# M031AE_v1 register map
File version: 1.0
Registers are 32-bit, read-write, reset 0x0 unless marked. A register's access mark holds for its fields unless they carry their own. Offsets are from the block's base; [hi:lo] are bit positions; {n}, {i} and the like mark numbered series.

## SYS — SYS Register Map
Base 0x40000000
0x00 SYS_PDID ro reset not defined — Part Device Identification Number Register
  [31:0] PDID — Part Device Identification Number (Read Only). This register reflects device part number code. Software can read this register to identify which device is used.
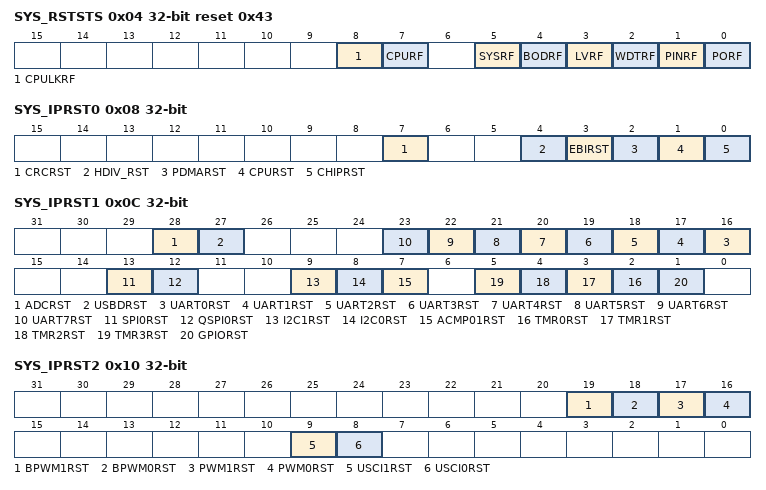
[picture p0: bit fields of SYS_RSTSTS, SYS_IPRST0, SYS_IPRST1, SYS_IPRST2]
0x04 SYS_RSTSTS reset 0x43 — System Reset Status Register
  [8] CPULKRF — CPU Lockup Reset Flag. Note: Write 1 to clear this bit to 0. Note 2: When CPU lockup happened under ICE is connected, This flag will set to 1 but chip will not reset.
    0=No reset from CPU lockup happened; 1=The Cortex-M0 lockup happened and chip is reset
  [7] CPURF — CPU Reset Flag. The CPU reset flag is set by hardware if software writes CPURST (SYS_IPRST0[1]) 1 to reset Cortex- M0 Core and Flash Memory Controller (FMC). Note: Write to clear this bit to 0.
    0=No reset from CPU; 1=The Cortex-M0 Core and FMC are reset by software setting CPURST to 1
  [5] SYSRF — System Reset Flag. The system reset flag is set by the 'Reset Signal' from the Cortex-M0 Core to indicate the previous reset source. Note: Write 1 to clear this bit to 0.
    0=No reset from Cortex-M0; 1=The Cortex- M0 had issued the reset signal to reset the system by writing 1 to the bit SYSRESETREQ(AIRCR[2], Application Interrupt and Reset Control Register, address = 0xE000ED0C) in system control registers of Cortex-M0 core
  [4] BODRF — BOD Reset Flag. The BOD reset flag is set by the 'Reset Signal' from the Brown-Out Detector to indicate the previous reset source. Note: Write 1 to clear this bit to 0.
    0=No reset from BOD; 1=The BOD had issued the reset signal to reset the system
  [3] LVRF — LVR Reset Flag. The LVR reset flag is set by the 'Reset Signal' from the Low Voltage Reset Controller to indicate the previous reset source. Note: Write 1 to clear this bit to 0.
    0=No reset from LVR; 1=LVR controller had issued the reset signal to reset the system
  [2] WDTRF — WDT Reset Flag. The WDT reset flag is set by the 'Reset Signal' from the Watchdog Timer or Window Watchdog Timer to indicate the previous reset source. Note 1: Write 1 to clear this bit to 0. Note 2: Watchdog Timer register RSTF(WDT_CTL[2]) bit is set if the system has been reset by WDT time-out reset. Window Watchdog Timer register WWDTRF(WWDT_STATUS[1]) bit is set if the system has been reset by WWDT time-out reset.
    0=No reset from watchdog timer or window watchdog timer; 1=The watchdog timer or window watchdog timer had issued the reset signal to reset the system
  [1] PINRF — NRESET Pin Reset Flag. The nRESET pin reset flag is set by the 'Reset Signal' from the nRESET Pin to indicate the previous reset source. Note: Write 1 to clear this bit to 0.
    0=No reset from nRESET pin; 1=Pin nRESET had issued the reset signal to reset the system
  [0] PORF — POR Reset Flag. The POR reset flag is set by the 'Reset Signal' from the Power-on Reset (POR) Controller or bit CHIPRST (SYS_IPRST0[0]) to indicate the previous reset source. Note: Write 1 to clear this bit to 0.
    0=No reset from POR or CHIPRST; 1=Power-on Reset (POR) or CHIPRST had issued the reset signal to reset the system
0x08 SYS_IPRST0 — Peripheral Reset Control Register 0
  [7] CRCRST — CRC Calculation Controller Reset (Write Protect). Set this bit to 1 will generate a reset signal to the CRC calculation controller. User needs to set this bit to 0 to release from the reset state. Note: This bit is write protected. Refer to the SYS_REGLCTL register.
    0=CRC calculation controller normal operation; 1=CRC calculation controller reset
  [4] HDIV_RST — HDIV Controller Reset (Write Protect). Set this bit to 1 will generate a reset signal to the hardware divider. User need to set this bit to 0 to release from the reset state. Note: This bit is write protected. Refer to the SYS_REGLCTL register.
    0=Hardware divider controller normal operation; 1=Hardware divider controller reset
  [3] EBIRST — EBI Controller Reset (Write Protect). Set this bit to 1 will generate a reset signal to the EBI. User needs to set this bit to 0 to release from the reset state. Note: This bit is write protected. Refer to the SYS_REGLCTL register.
    0=EBI controller normal operation; 1=EBI controller reset
  [2] PDMARST — PDMA Controller Reset (Write Protect). Setting this bit to 1 will generate a reset signal to the PDMA. User needs to set this bit to 0 to release from reset state. Note: This bit is write protected. Refer to the SYS_REGLCTL register.
    0=PDMA controller normal operation; 1=PDMA controller reset
  [1] CPURST — Processor Core One-shot Reset (Write Protect). Setting this bit will only reset the processor core and Flash Memory Controller(FMC), and this bit will automatically return to 0 after the 2 clock cycles. Note: This bit is write protected. Refer to the SYS_REGLCTL register.
    0=Processor core normal operation; 1=Processor core one-shot reset
  [0] CHIPRST — Chip One-shot Reset (Write Protect). Setting this bit will reset the whole chip, including Processor core and all peripherals, and this bit will automatically return to 0 after the 2 clock cycles. The CHIPRST is same as the POR reset, all the chip controllers is reset and the chip setting from Flash are also reload. About the difference between CHIPRST and SYSRESETREQ(AIRCR[2]), please refer to section 6.2.2. Note: This bit is write protected. Refer to the SYS_REGLCTL register. Note : reset by powr on reset
    0=Chip normal operation; 1=Chip one-shot reset
0x0C SYS_IPRST1 — Peripheral Reset Control Register 1
  [28] ADCRST — ADC Controller Reset
    0=ADC controller normal operation; 1=ADC controller reset
  [27] USBDRST — USBD Controller Reset
    0=USBD controller normal operation; 1=USBD controller reset
  [n+16] UART{n}RST (n=0..7) — UART{n} Controller Reset
    0=UART{n} controller normal operation; 1=UART{n} controller reset
  [13] SPI0RST — SPI0 Controller Reset
    0=SPI0 controller normal operation; 1=SPI0 controller reset
  [12] QSPI0RST — QSPI0 Controller Reset
    0=QSPI0 controller normal operation; 1=QSPI0 controller reset
  [9] I2C1RST — I2C1 Controller Reset
    0=I2C1 controller normal operation; 1=I2C1 controller reset
  [8] I2C0RST — I2C0 Controller Reset
    0=I2C0 controller normal operation; 1=I2C0 controller reset
  [7] ACMP01RST — Analog Comparator 0/1 Controller Reset
    0=Analog Comparator 0/1 controller normal operation; 1=Analog Comparator 0/1 controller reset
  [n+2] TMR{n}RST (n=0..3) — Timer{n} Controller Reset
    0=Timer{n} controller normal operation; 1=Timer{n} controller reset
  [1] GPIORST — GPIO Controller Reset
    0=GPIO controller normal operation; 1=GPIO controller reset
0x10 SYS_IPRST2 — Peripheral Reset Control Register 2
  [19] BPWM1RST — BPWM1 Controller Reset
    0=BPWM1 controller normal operation; 1=BPWM1 controller reset
  [18] BPWM0RST — BPWM0 Controller Reset
    0=BPWM0 controller normal operation; 1=BPWM0 controller reset
  [17] PWM1RST — PWM1 Controller Reset
    0=PWM1 controller normal operation; 1=PWM1 controller reset
  [16] PWM0RST — PWM0 Controller Reset
    0=PWM0 controller normal operation; 1=PWM0 controller reset
  [9] USCI1RST — USCI1 Controller Reset
    0=USCI1 controller normal operation; 1=USCI1 controller reset
  [8] USCI0RST — USCI0 Controller Reset
    0=USCI0 controller normal operation; 1=USCI0 controller reset
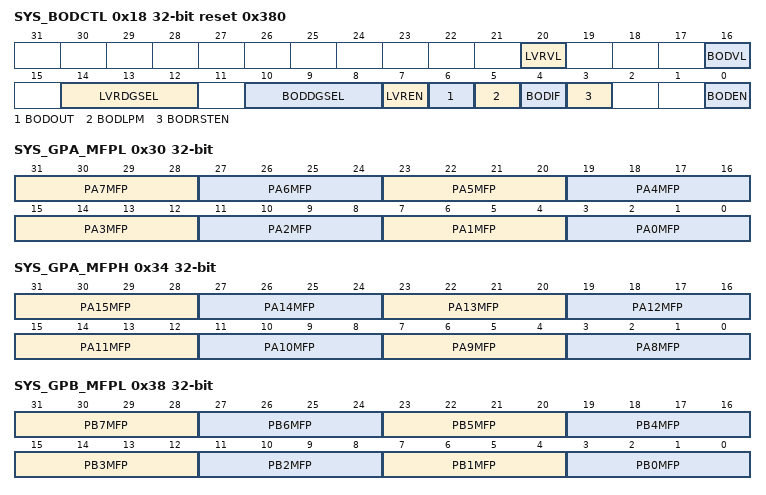
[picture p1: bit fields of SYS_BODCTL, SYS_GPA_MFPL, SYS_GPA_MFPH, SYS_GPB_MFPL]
0x18 SYS_BODCTL reset 0x380 (reset mask 0xFF00FFF0) — Brown-out Detector Control Register
  [20] LVRVL — LVR Detector Threshold Voltage Selection (Write Protect). The default value is set by Flash controller user configuration register LVRLVSEL (CONFIG0 [29]). Note 1: This bit is write protected. Refer to the SYS_REGLCTL register. Note 2: This bit is only for special case. Note 3: reset by powr on reset
    0=LVR-Out Detector threshold voltage is 1.6V; 1=LVR-Out Detector threshold voltage is 1.7V
  [16] BODVL — Brown-out Detector Threshold Voltage Selection (Write Protect). The default value is set by Flash controller user configuration register CBOV (CONFIG0 [21]). Note: This bit is write protected. Refer to the SYS_REGLCTL register. Note : reset by powr on reset
    0=Brown-Out Detector threshold voltage is 2.0V; 1=Brown-Out Detector threshold voltage is 2.5V
  [14:12] LVRDGSEL — LVR Output De-glitch Time Select (Write Protect). Note: These bits are write protected. Refer to the SYS_REGLCTL register.
    0=Without de-glitch function; 1=64 system clock (HCLK); 2=128 system clock (HCLK); 3=256 system clock (HCLK); 4=512 system clock (HCLK); 5=1024 system clock (HCLK); 6=2048 system clock (HCLK); 7=4096 system clock (HCLK)
  [10:8] BODDGSEL — Brown-out Detector Output De-glitch Time Select (Write Protect). Note: These bits are write protected. Refer to the SYS_REGLCTL register.
    0=BOD output is sampled by LIRC/4 clock; 1=64 system clock (HCLK); 2=128 system clock (HCLK); 3=256 system clock (HCLK); 4=512 system clock (HCLK); 5=1024 system clock (HCLK); 6=2048 system clock (HCLK); 7=4096 system clock (HCLK)
  [7] LVREN — Low Voltage Reset Enable Bit (Write Protect). The LVR function resets the chip when the input power voltage is lower than LVR circuit setting. LVR function is enabled by default. Note 1: After enabling the bit, the LVR function will be active with 200us delay for LVR output stable (default). Note 2: This bit is write protected. Refer to the SYS_REGLCTL register.
    0=Low Voltage Reset function Disabled; 1=Low Voltage Reset function Enabled
  [6] BODOUT — Brown-out Detector Output Status. It means the detected voltage is lower than BODVL setting. If the BODEN is 0, BOD function disabled , this bit always responds 0000.
    0=Brown-out Detector output status is 0; 1=Brown-out Detector output status is 1
  [5] BODLPM — Brown-out Detector Low Power Mode (Write Protect). Note 1: The BOD consumes about 100uA in normal mode, the low power mode can reduce the current to about 1/10 but slow the BOD response. Note 2: This bit is write protected. Refer to the SYS_REGLCTL register.
    0=BOD operate in normal mode (default); 1=BOD Low Power mode Enabled
  [4] BODIF — Brown-out Detector Interrupt Flag. Note: Write 1 to clear this bit to 0.
    0=Brown-out Detector does not detect any voltage draft at VDD down through or up through the voltage of BODVL setting; 1=When Brown-out Detector detects the VDD is dropped down through the voltage of BODVL setting or the VDD is raised up through the voltage of BODVL setting, this bit is set to 1 and the brown-out interrupt is requested if brown-out interrupt is enabled
  [3] BODRSTEN — Brown-out Reset Enable Bit (Write Protect). The default value is set by Flash controller user configuration register CBORST(CONFIG0[20]) bit . Note 1: While the Brown-out Detector function is enabled (BODEN high) and BOD reset function is enabled (BODRSTEN high), BOD will assert a signal to reset chip when the detected voltage is lower than the threshold (BODOUT high). While the BOD function is enabled (BODEN high) and BOD interrupt function is enabled (BODRSTEN low), BOD will assert an interrupt if BODOUT is high. BOD interrupt will keep till to the BODEN set to 0. BOD interrupt can be blocked by disabling the NVIC BOD interrupt or disabling BOD function (set BODEN low). Note 2: This bit is write protected. Refer to the SYS_REGLCTL register. Note 3: Reset by powr on reset
    0=Brown-out 'INTERRUPT' function Enabled; 1=Brown-out 'RESET' function Enabled
  [0] BODEN — Brown-out Detector Enable Bit (Write Protect). The default value is set by Flash controller user configuration register CBODEN (CONFIG0 [19]). Note 1: This bit is write protected. Refer to the SYS_REGLCTL register. Note 2: Reset by powr on reset
    0=Brown-out Detector function Disabled; 1=Brown-out Detector function Enabled
0x24 SYS_PORCTL — Power-On-reset Controller Register
  [15:0] POROFF — Power-on Reset Enable Bit (Write Protect). When powered on, the POR circuit generates a reset signal to reset the whole chip function, but noise on the power may cause the POR active again. User can disable internal POR circuit to avoid unpredictable noise to cause chip reset by writing 0x5AA5 to this field. The POR function will be active again when this field is set to another value or chip is reset by other reset source, including: nRESET, Watchdog, LVR reset, BOD reset, ICE reset command and the software-chip reset function. Note: This bit is write protected. Refer to the SYS_REGLCTL register.
0x30 SYS_GPA_MFPL — GPIOA Low Byte Multiple Function Control Register
  [31:28] PA7MFP — PA.7 Multi-function Pin Selection
  [27:24] PA6MFP — PA.6 Multi-function Pin Selection
  [23:20] PA5MFP — PA.5 Multi-function Pin Selection
  [19:16] PA4MFP — PA.4 Multi-function Pin Selection
  [15:12] PA3MFP — PA.3 Multi-function Pin Selection
  [11:8] PA2MFP — PA.2 Multi-function Pin Selection
  [7:4] PA1MFP — PA.1 Multi-function Pin Selection
  [3:0] PA0MFP — PA.0 Multi-function Pin Selection
0x34 SYS_GPA_MFPH — GPIOA High Byte Multiple Function Control Register
  [31:28] PA15MFP — PA.15 Multi-function Pin Selection
  [27:24] PA14MFP — PA.14 Multi-function Pin Selection
  [23:20] PA13MFP — PA.13 Multi-function Pin Selection
  [19:16] PA12MFP — PA.12 Multi-function Pin Selection
  [15:12] PA11MFP — PA.11 Multi-function Pin Selection
  [11:8] PA10MFP — PA.10 Multi-function Pin Selection
  [7:4] PA9MFP — PA.9 Multi-function Pin Selection
  [3:0] PA8MFP — PA.8 Multi-function Pin Selection
0x38 SYS_GPB_MFPL — GPIOB Low Byte Multiple Function Control Register
  [31:28] PB7MFP — PB.7 Multi-function Pin Selection
  [27:24] PB6MFP — PB.6 Multi-function Pin Selection
  [23:20] PB5MFP — PB.5 Multi-function Pin Selection
  [19:16] PB4MFP — PB.4 Multi-function Pin Selection
  [15:12] PB3MFP — PB.3 Multi-function Pin Selection
  [11:8] PB2MFP — PB.2 Multi-function Pin Selection
  [7:4] PB1MFP — PB.1 Multi-function Pin Selection
  [3:0] PB0MFP — PB.0 Multi-function Pin Selection
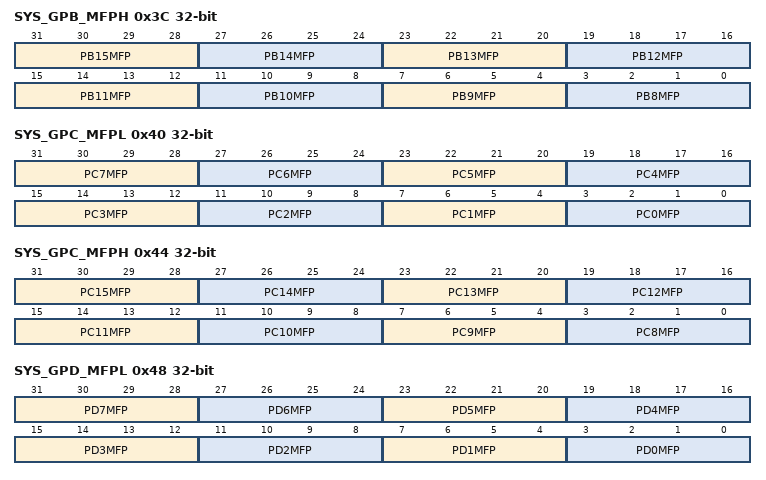
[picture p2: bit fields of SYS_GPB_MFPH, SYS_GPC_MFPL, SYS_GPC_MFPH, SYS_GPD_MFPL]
0x3C SYS_GPB_MFPH — GPIOB High Byte Multiple Function Control Register
  [31:28] PB15MFP — PB.15 Multi-function Pin Selection
  [27:24] PB14MFP — PB.14 Multi-function Pin Selection
  [23:20] PB13MFP — PB.13 Multi-function Pin Selection
  [19:16] PB12MFP — PB.12 Multi-function Pin Selection
  [15:12] PB11MFP — PB.11 Multi-function Pin Selection
  [11:8] PB10MFP — PB.10 Multi-function Pin Selection
  [7:4] PB9MFP — PB.9 Multi-function Pin Selection
  [3:0] PB8MFP — PB.8 Multi-function Pin Selection
0x40 SYS_GPC_MFPL — GPIOC Low Byte Multiple Function Control Register
  [31:28] PC7MFP — PC.7 Multi-function Pin Selection
  [27:24] PC6MFP — PC.6 Multi-function Pin Selection
  [23:20] PC5MFP — PC.5 Multi-function Pin Selection
  [19:16] PC4MFP — PC.4 Multi-function Pin Selection
  [15:12] PC3MFP — PC.3 Multi-function Pin Selection
  [11:8] PC2MFP — PC.2 Multi-function Pin Selection
  [7:4] PC1MFP — PC.1 Multi-function Pin Selection
  [3:0] PC0MFP — PC.0 Multi-function Pin Selection
0x44 SYS_GPC_MFPH — GPIOC High Byte Multiple Function Control Register
  [31:28] PC15MFP — PC.15 Multi-function Pin Selection
  [27:24] PC14MFP — PC.14 Multi-function Pin Selection
  [23:20] PC13MFP — PC.13 Multi-function Pin Selection
  [19:16] PC12MFP — PC.12 Multi-function Pin Selection
  [15:12] PC11MFP — PC.11 Multi-function Pin Selection
  [11:8] PC10MFP — PC.10 Multi-function Pin Selection
  [7:4] PC9MFP — PC.9 Multi-function Pin Selection
  [3:0] PC8MFP — PC.8 Multi-function Pin Selection
0x48 SYS_GPD_MFPL — GPIOD Low Byte Multiple Function Control Register
  [31:28] PD7MFP — PD.7 Multi-function Pin Selection
  [27:24] PD6MFP — PD.6 Multi-function Pin Selection
  [23:20] PD5MFP — PD.5 Multi-function Pin Selection
  [19:16] PD4MFP — PD.4 Multi-function Pin Selection
  [15:12] PD3MFP — PD.3 Multi-function Pin Selection
  [11:8] PD2MFP — PD.2 Multi-function Pin Selection
  [7:4] PD1MFP — PD.1 Multi-function Pin Selection
  [3:0] PD0MFP — PD.0 Multi-function Pin Selection
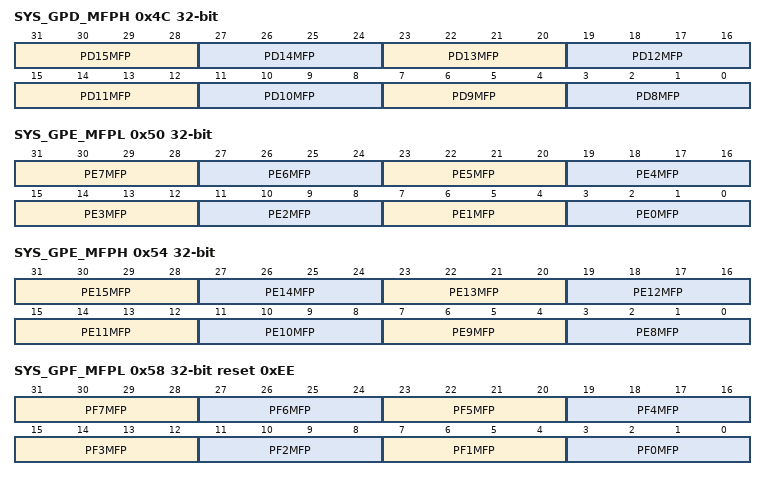
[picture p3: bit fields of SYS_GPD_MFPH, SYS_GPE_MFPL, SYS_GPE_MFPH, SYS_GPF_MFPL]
0x4C SYS_GPD_MFPH — GPIOD High Byte Multiple Function Control Register
  [31:28] PD15MFP — PD.15 Multi-function Pin Selection
  [27:24] PD14MFP — PD.14 Multi-function Pin Selection
  [23:20] PD13MFP — PD.13 Multi-function Pin Selection
  [19:16] PD12MFP — PD.12 Multi-function Pin Selection
  [15:12] PD11MFP — PD.11 Multi-function Pin Selection
  [11:8] PD10MFP — PD.10 Multi-function Pin Selection
  [7:4] PD9MFP — PD.9 Multi-function Pin Selection
  [3:0] PD8MFP — PD.8 Multi-function Pin Selection
0x50 SYS_GPE_MFPL — GPIOE Low Byte Multiple Function Control Register
  [31:28] PE7MFP — PE.7 Multi-function Pin Selection
  [27:24] PE6MFP — PE.6 Multi-function Pin Selection
  [23:20] PE5MFP — PE.5 Multi-function Pin Selection
  [19:16] PE4MFP — PE.4 Multi-function Pin Selection
  [15:12] PE3MFP — PE.3 Multi-function Pin Selection
  [11:8] PE2MFP — PE.2 Multi-function Pin Selection
  [7:4] PE1MFP — PE.1 Multi-function Pin Selection
  [3:0] PE0MFP — PE.0 Multi-function Pin Selection
0x54 SYS_GPE_MFPH — GPIOE High Byte Multiple Function Control Register
  [31:28] PE15MFP — PE.15 Multi-function Pin Selection
  [27:24] PE14MFP — PE.14 Multi-function Pin Selection
  [23:20] PE13MFP — PE.13 Multi-function Pin Selection
  [19:16] PE12MFP — PE.12 Multi-function Pin Selection
  [15:12] PE11MFP — PE.11 Multi-function Pin Selection
  [11:8] PE10MFP — PE.10 Multi-function Pin Selection
  [7:4] PE9MFP — PE.9 Multi-function Pin Selection
  [3:0] PE8MFP — PE.8 Multi-function Pin Selection
0x58 SYS_GPF_MFPL reset 0xEE — GPIOF Low Byte Multiple Function Control Register
  [31:28] PF7MFP — PF.7 Multi-function Pin Selection
  [27:24] PF6MFP — PF.6 Multi-function Pin Selection
  [23:20] PF5MFP — PF.5 Multi-function Pin Selection
  [19:16] PF4MFP — PF.4 Multi-function Pin Selection
  [15:12] PF3MFP — PF.3 Multi-function Pin Selection
  [11:8] PF2MFP — PF.2 Multi-function Pin Selection
  [7:4] PF1MFP — PF.1 Multi-function Pin Selection
  [3:0] PF0MFP — PF.0 Multi-function Pin Selection
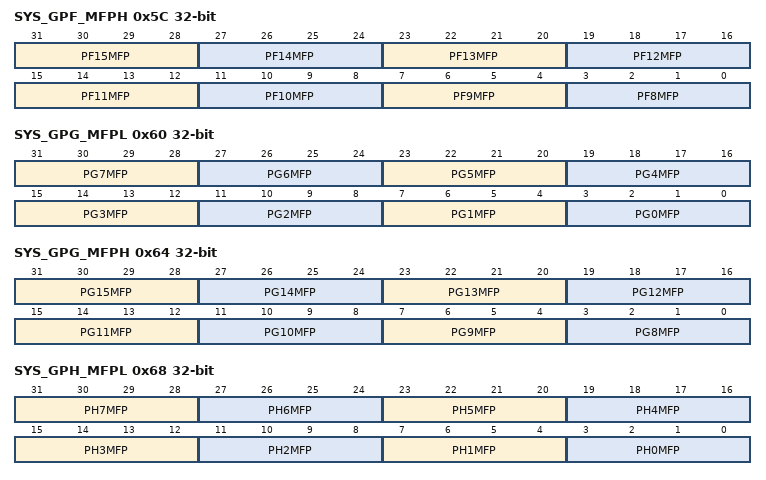
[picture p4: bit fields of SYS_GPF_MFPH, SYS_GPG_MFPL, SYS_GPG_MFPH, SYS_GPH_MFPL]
0x5C SYS_GPF_MFPH — GPIOF High Byte Multiple Function Control Register
  [31:28] PF15MFP — PF.15 Multi-function Pin Selection
  [27:24] PF14MFP — PF.14 Multi-function Pin Selection
  [23:20] PF13MFP — PF.13 Multi-function Pin Selection
  [19:16] PF12MFP — PF.12 Multi-function Pin Selection
  [15:12] PF11MFP — PF.11 Multi-function Pin Selection
  [11:8] PF10MFP — PF.10 Multi-function Pin Selection
  [7:4] PF9MFP — PF.9 Multi-function Pin Selection
  [3:0] PF8MFP — PF.8 Multi-function Pin Selection
0x60 SYS_GPG_MFPL — GPIOG Low Byte Multiple Function Control Register
  [31:28] PG7MFP — PG.7 Multi-function Pin Selection
  [27:24] PG6MFP — PG.6 Multi-function Pin Selection
  [23:20] PG5MFP — PG.5 Multi-function Pin Selection
  [19:16] PG4MFP — PG.4 Multi-function Pin Selection
  [15:12] PG3MFP — PG.3 Multi-function Pin Selection
  [11:8] PG2MFP — PG.2 Multi-function Pin Selection
  [7:4] PG1MFP — PG.1 Multi-function Pin Selection
  [3:0] PG0MFP — PG.0 Multi-function Pin Selection
0x64 SYS_GPG_MFPH — GPIOG High Byte Multiple Function Control Register
  [31:28] PG15MFP — PG.15 Multi-function Pin Selection
  [27:24] PG14MFP — PG.14 Multi-function Pin Selection
  [23:20] PG13MFP — PG.13 Multi-function Pin Selection
  [19:16] PG12MFP — PG.12 Multi-function Pin Selection
  [15:12] PG11MFP — PG.11 Multi-function Pin Selection
  [11:8] PG10MFP — PG.10 Multi-function Pin Selection
  [7:4] PG9MFP — PG.9 Multi-function Pin Selection
  [3:0] PG8MFP — PG.8 Multi-function Pin Selection
0x68 SYS_GPH_MFPL — GPIOH Low Byte Multiple Function Control Register
  [31:28] PH7MFP — PH.7 Multi-function Pin Selection
  [27:24] PH6MFP — PH.6 Multi-function Pin Selection
  [23:20] PH5MFP — PH.5 Multi-function Pin Selection
  [19:16] PH4MFP — PH.4 Multi-function Pin Selection
  [15:12] PH3MFP — PH.3 Multi-function Pin Selection
  [11:8] PH2MFP — PH.2 Multi-function Pin Selection
  [7:4] PH1MFP — PH.1 Multi-function Pin Selection
  [3:0] PH0MFP — PH.0 Multi-function Pin Selection
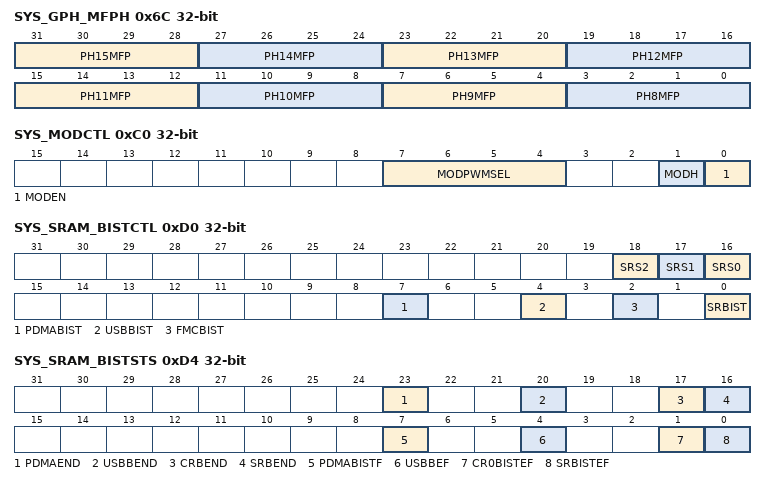
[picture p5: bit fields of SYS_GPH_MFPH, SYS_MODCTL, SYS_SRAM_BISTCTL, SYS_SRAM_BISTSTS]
0x6C SYS_GPH_MFPH — GPIOH High Byte Multiple Function Control Register
  [31:28] PH15MFP — PH.15 Multi-function Pin Selection
  [27:24] PH14MFP — PH.14 Multi-function Pin Selection
  [23:20] PH13MFP — PH.13 Multi-function Pin Selection
  [19:16] PH12MFP — PH.12 Multi-function Pin Selection
  [15:12] PH11MFP — PH.11 Multi-function Pin Selection
  [11:8] PH10MFP — PH.10 Multi-function Pin Selection
  [7:4] PH9MFP — PH.9 Multi-function Pin Selection
  [3:0] PH8MFP — PH.8 Multi-function Pin Selection
0xC0 SYS_MODCTL — Modulation Control Register
  [7:4] MODPWMSEL — PWM0 Channel Select for Modulation. Select the PWM0 channel to modulate with the UART0_TXD or USCI0_DAT0. 0000: PWM0 Channel 0 modulate with UART0_TXD. 0001: PWM0 Channel 1 modulate with UART0_TXD. 0010: PWM0 Channel 2 modulate with UART0_TXD. 0011: PWM0 Channel 3 modulete with UART0_TXD. 0100: PWM0 Channel 4 modulete with UART0_TXD. 0101: PWM0 Channel 5 modulete with UART0_TXD. 0110: Reserved. 0111: Reserved. 1000: PWM0 Channel 0 modulate with USCI0_DAT0. 1001: PWM0 Channel 1 modulate with USCI0_DAT0. 1010: PWM0 Channel 2 modulate with USCI0_DAT0. 1011: PWM0 Channel 3 modulete with USCI0_DAT0. 1100: PWM0 Channel 4 modulete with USCI0_DAT0. 1101: PWM0 Channel 5 modulete with USCI0_DAT0. 1110: Reserved. 1111: Reserved. Note: This bis is valid while MODEN (SYS_MODCTL[0]) is set to 1.
  [1] MODH — Modulation at Data High. Select modulation pulse(PWM0) at high or low of UART0_TXD or USCI0_DAT0. 0: Modulation pulse at UART0_TXD low or USCI0_DAT0 low. 1: Modulation pulse at UART0_TXD high or USCI0_DAT0 high.
  [0] MODEN — Modulation Function Enable Bit. This bit enables modulation funcion by modulating with PWM0 channel output and USCI0(USCI0_DAT0) or UART0(UART0_TXD) output.
    0=Modulation Function Disabled; 1=Modulation Function Enabled
0xD0 SYS_SRAM_BISTCTL (reset mask 0xFFF0FFFF) — System SRAM BIST Test Control Register
  [18] SRS2 — SRAM Bank0 Section 2 BIST Select (Write Protect). This bit define if the bank0 section2 (0x2001_0000~0x2001_7FFF) of SRAM is selected or not when doing bist test. Note: This bit is write protected. Refer to the SYS_REGLCTL register. Note: At least one section of SRAM should be selected when doing SRAM bist test.
    0=SRAM back0 section2 is deselected when doing bist test; 1=SRAM back0 section2 is selected when doing bist test
  [17] SRS1 — SRAM Bank0 Section 1 BIST Select (Write Protect). This bit define if the bank0 section1 (0x2000_8000~0x2000_FFFF) of SRAM is selected or not when doing bist test. Note: This bit is write protected. Refer to the SYS_REGLCTL register. Note: At least one section of SRAM should be selected when doing SRAM bist test.
    0=SRAM bank0 section1 is deselected when doing bist test; 1=SRAM bank0 section1 is selected when doing bist test
  [16] SRS0 — SRAM Bank0 Section 0 BIST Select (Write Protect). This bit define if the bank0 section0 (0x2000_0000~0x2000_7FFF) of SRAM is selected or not when doing bist test. Note: This bit is write protected. Refer to the SYS_REGLCTL register. Note: At least one section of SRAM should be selected when doing SRAM bist test.
    0=SRAM bank0 section0 is deselected when doing bist test; 1=SRAM bank0 section0 is selected when doing bist test
  [7] PDMABIST — PDMA BIST Enable Bit (Write Protect). This bit enables BIST test for PDMA RAM. Note: This bit is write protected. Refer to the SYS_REGLCTL register.
    0=system PDMA BIST Disabled; 1=system PDMA BIST Enabled
  [4] USBBIST — USB BIST Enable Bit (Write Protect). This bit enables BIST test for USB RAM. Note: This bit is write protected. Refer to the SYS_REGLCTL register.
    0=system USB BIST Disabled; 1=system USB BIST Enabled
  [2] FMCBIST — FMC CACHE BIST Enable Bit (Write Protect). This bit enables BIST test for CACHE RAM. Note: This bit is write protected. Refer to the SYS_REGLCTL register.
    0=System CACHE BIST Disabled; 1=System CACHE BIST Enabled
  [0] SRBIST — SRAM BIST Enable Bit (Write Protect). This bit enables BIST test for SRAM. Note: This bit is write protected. Refer to the SYS_REGLCTL register.
    0=system SRAM BIST Disabled; 1=system SRAM BIST Enabled
0xD4 SYS_SRAM_BISTSTS ro (reset mask 0xFF00FF00) — System SRAM BIST Test Status Register
  [23] PDMAEND — PDMA SRAM BIST Test Finish
    0=PDMA SRAM BIST is active; 1=PDMA SRAM BIST test finish
  [20] USBBEND — USB SRAM BIST Test Finish
    0=USB SRAM BIST is active; 1=USB SRAM BIST test finish
  [17] CRBEND — CACHE SRAM BIST Test Finish
    0=System CACHE RAM BIST is active; 1=System CACHE RAM BIST test finished
  [16] SRBEND — System SRAM BIST Test Finish
    0=System SRAM BIST active; 1=System SRAM BIST finish
  [7] PDMABISTF — PDMA SRAM BIST Failed Flag
    0=PDMA SRAM BIST pass; 1=PDMA SRAM BIST failed
  [4] USBBEF — USB SRAM BIST Fail Flag
    0=USB SRAM BIST test pass; 1=USB SRAM BIST test fail
  [1] CR0BISTEF — CACHE SRAM BIST Fail Flag
    0=System CACHE RAM BIST test pass; 1=System CACHE RAM BIST test failed
  [0] SRBISTEF — System SRAM BIST Fail Flag
    0=System SRAM BIST test pass; 1=System SRAM BIST test fail
0xDC SYS_SRAM_INTCTL — System SRAM Interrupt Enable Control Register
  [0] PERRIEN — SRAM Parity Check Error Interrupt Enable Bit
    0=SRAM parity check error interrupt Disabled; 1=SRAM parity check error interrupt Enabled
0xE0 SYS_SRAM_STATUS — System SRAM Parity Error Status Register
  [0] PERRIF — SRAM Parity Check Error Flag. This bit indicates the System SRAM parity error occurred. Write 1 to clear this to 0.
    0=No System SRAM parity error; 1=System SRAM parity error occur
0xE4 SYS_SRAM_ERRADDR ro — System SRAM Parity Check Error Address Register
  [31:0] ERRADDR — System SRAM Parity Error Address. This register shows system SRAM parity error byte address.
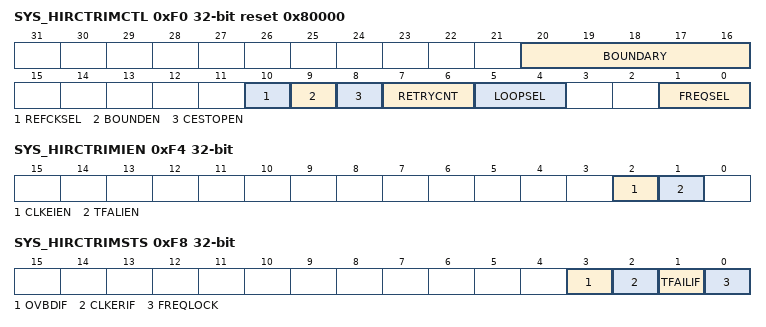
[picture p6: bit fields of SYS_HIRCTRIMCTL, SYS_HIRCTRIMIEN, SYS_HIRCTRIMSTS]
0xF0 SYS_HIRCTRIMCTL reset 0x80000 — HIRC Trim Control Register
  [20:16] BOUNDARY — Boundary Selection. Fill the boundary range from 0x1 to 0x1F, 0x0 is reserved. Note: This field is effective only when the BOUNDEN(SYS_HIRCTRIMCTL[9]) is enable.
  [10] REFCKSEL — Reference Clock Selection. Note 1: HIRC trim reference clock supports LXT or internal USB synchronous mode depending on the chip spec. Please refer to section 3.2 NuMicro M031/M032 Series Selection Guide for detailed information. Note 2: If there is no reference clock (LXT or internal USB synchronous mode) when the rc_trim is enabled, CLKERIF (SYS_HIRCTRIMCTL[2]) will be set to 1.
    0=HIRC trim reference clock is from LXT (32.768 kHz); 1=HIRC trim reference clock is from internal USB synchronous mode
  [9] BOUNDEN — Boundary Enable Bit
    0=Boundary function Disabled; 1=Boundary function Enabled
  [8] CESTOPEN — Clock Error Stop Enable Bit
    0=The trim operation is keep going if clock is inaccuracy; 1=The trim operation is stopped if clock is inaccuracy
  [7:6] RETRYCNT — Trim Value Update Limitation Count. This field defines that how many times the auto trim circuit will try to update the HIRC trim value before the frequency of HIRC locked. Once the HIRC locked, the internal trim value update counter will be reset. If the trim value update counter reached this limitation value and frequency of HIRC still doesn't lock, the auto trim operation will be disabled and FREQSEL will be cleared to 00.
    0=Trim retry count limitation is 64 loops; 1=Trim retry count limitation is 128 loops; 2=Trim retry count limitation is 256 loops; 3=Trim retry count limitation is 512 loops
  [5:4] LOOPSEL — Trim Calculation Loop Selection. This field defines that trim value calculation is based on how many reference clocks. Note: For example, if LOOPSEL is set as 00, auto trim circuit will calculate trim value based on the average frequency difference in 4 clocks of reference clock.
    0=Trim value calculation is based on average difference in 4 clocks of reference clock; 1=Trim value calculation is based on average difference in 8 clocks of reference clock; 2=Trim value calculation is based on average difference in 16 clocks of reference clock; 3=Trim value calculation is based on average difference in 32 clocks of reference clock
  [1:0] FREQSEL — Trim Frequency Selection. This field indicates the target frequency of 48 MHz internal high speed RC oscillator (HIRC) auto trim. During auto trim operation, if clock error detected with CESTOPEN is set to 1 or trim retry limitation count reached, this field will be cleared to 00 automatically.
    0=Disable HIRC auto trim function; 1=Enable HIRC auto trim function and trim HIRC to 48 MHz
0xF4 SYS_HIRCTRIMIEN — HIRC Trim Interrupt Enable Register
  [2] CLKEIEN — Clock Error Interrupt Enable Bit. This bit controls if CPU would get an interrupt while clock is inaccuracy during auto trim operation. If this bit is set to1, and CLKERRIF(SYS_HIRCTRIMSTS[2]) is set during auto trim operation, an interrupt will be triggered to notify the clock frequency is inaccuracy.
    0=Disable CLKERRIF(SYS_HIRCTRIMSTS[2]) status to trigger an interrupt to CPU; 1=Enable CLKERRIF(SYS_HIRCTRIMSTS[2]) status to trigger an interrupt to CPU
  [1] TFALIEN — Trim Failure Interrupt Enable Bit. This bit controls if an interrupt will be triggered while HIRC trim value update limitation count reached and HIRC frequency still not locked on target frequency set by FREQSEL(SYS_HIRCTRIMCTL[1:0]). If this bit is high and TFAILIF(SYS_HIRCTRIMSTS[1]) is set during auto trim operation, an interrupt will be triggered to notify that HIRC trim value update limitation count was reached.
    0=Disable TFAILIF(SYS_HIRCTRIMSTS[1]) status to trigger an interrupt to CPU; 1=Enable TFAILIF(SYS_HIRCTRIMSTS[1]) status to trigger an interrupt to CPU
0xF8 SYS_HIRCTRIMSTS — HIRC Trim Interrupt Status Register
  [3] OVBDIF — Over Boundary Status. When the over boundary function is set, if there occurs the over boundary condition, this flag will be set. Note: Write 1 to clear this flag.
    0=Over boundary coundition did not occur; 1=Over boundary coundition occurred
  [2] CLKERIF — Clock Error Interrupt Status. When the frequency relation between reference clock (LXT or USB sync signals) and 48 MHz internal high speed RC oscillator (HIRC) is shift larger to unreasonable value, this bit will be set and to be an indicate that clock frequency is inaccuracy. Once this bit is set to 1, the auto trim operation stopped and FREQSEL(SYS_HIRCTRIMCTL[1:0]) will be cleared to 00 by hardware automatically if CESTOPEN(SYS_HIRCTRIMCTL[8]) is set to 1. If this bit is set and CLKEIEN(SYS_HIRCTIEN[2]) is high, an interrupt will be triggered to notify the clock frequency is inaccuracy. Write 1 to clear this to 0. Note : Reset by powr on reset
    0=Clock frequency is accuracy; 1=Clock frequency is inaccuracy
  [1] TFAILIF — Trim Failure Interrupt Status. This bit indicates that HIRC trim value update limitation count reached and the HIRC clock frequency still doesn't be locked. Once this bit is set, the auto trim operation stopped and FREQSEL(SYS_HIRCTRIMCTL[1:0]) will be cleared to 00 by hardware automatically. If this bit is set and TFAILIEN(SYS_HIRCIEN[1]) is high, an interrupt will be triggered to notify that HIRC trim value update limitation count was reached. Write 1 to clear this to 0. Note : Reset by powr on reset
    0=Trim value update limitation count does not reach; 1=Trim value update limitation count reached and HIRC frequency still not locked
  [0] FREQLOCK — HIRC Frequency Lock Status. This bit indicates the HIRC frequency is locked. This is a status bit and doesn't trigger any interrupt. Write 1 to clear this to 0. This bit will be set automatically, if the frequecy is lock and the RC_TRIM is enabled. Note : Reset by powr on reset.
    0=The internal high-speed oscillator frequency doesn't lock at 48 MHz yet; 1=The internal high-speed oscillator frequency locked at 48 MHz
0x100 SYS_REGLCTL — Register Lock Control Register
  [7:0] REGLCTL — Register Lock Control Code (Write Only). Some registers have write-protection function. Writing these registers have to disable the protected function by writing the sequence value '59h', '16h', '88h' to this field. After this sequence is completed, the REGLCTL bit will be set to 1 and write-protection registers can be normal write. REGLCTL[0]. Register Lock Control Disable Index (Read Only)
    0=Write-protection Enabled for writing protected registers. Any write to the protected register is ignored; 1=Write-protection Disabled for writing protected registers
0x1EC SYS_PORDISAN — Analog POR Disable Control Register
  [15:0] POROFFAN — Power-on Reset Enable Bit (Write Protect). After powered on, User can turn off internal analog POR circuit to save power by writing 0x5AA5 to this field. The analog POR circuit will be active again when this field is set to another value or chip is reset by other reset source, including: nRESET, Watchdog, LVR reset, BOD reset, ICE reset command and the software-chip reset function. Note: This bit is write protected. Refer to the SYS_REGLCTL register.
